# f280015x_pbist_regs register map
Vendor: Texas Instruments
Peripheral module from a debugger description file (folder C2000).
Address unit: 16 bits
Registers are 32-bit, read-write, no defined reset value unless marked. A register's access mark holds for its fields unless they carry their own. Offsets are as the file gives them; lines under a group give offsets from that group; [hi:lo] are bit positions; {n}, {i} and the like mark numbered series; 'fields as' and 'values as' point back to an identical list; <NAME> marks a mode.

## PBIST_REGS — PBIST Registers
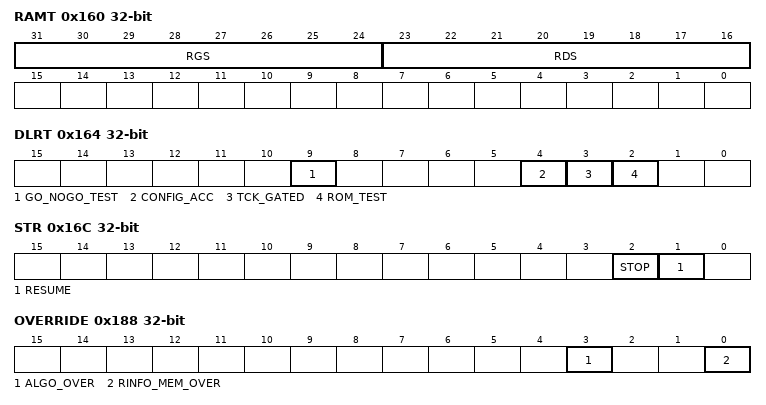
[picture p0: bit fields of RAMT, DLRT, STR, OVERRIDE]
0x160 RAMT — RAM Configuration Register
  [31:24] RGS — RAM Group Select
  [23:16] RDS — Return Data Select
0x164 DLRT — PBIST Data Logger Register
  [9] GO_NOGO_TEST — GO/ NO-GO Testing
  [4] CONFIG_ACC — Config Access
  [3] TCK_GATED
  [2] ROM_TEST — ROM-based testing
0x16C STR — Program Control Register
  [2] STOP — Stops PBIST testing
  [1] RESUME — Resume / Emulation Read
0x180 PACT — PBIST Activate Register
  [0] ENABLE — Enable clocks to PBIST
0x188 OVERRIDE — PBIST Override Register
  [3] ALGO_OVER — ROM Algorithm Override
  [0] RINFO_MEM_OVER — ROM Memory Information Override
0x190 FSRF0 — Fail Status - Port 0
  [31:0] FSRF0 — Fail Status Fail - Port 0
0x194 FSRF1 — Fail Status - Port 1
  [31:0] FSRF1 — Fail Status Fail - Port 1
0x198 FSRC0 — Fail Status Count - Port 0
0x19C FSRC1 — Fail Status Count - Port 1
  [31:0] FSRC0
0x1C4 ALGO — PBIST Algorithm
  [31:0] ALGO — Algo Select Register
0x1C8 RINFOL — RAM Info Mask Register Lower
  [31:0] RINFOL — RINFO Mask Register Lower
0x1CC RINFOU — RAM Info Mask Register Higher
  [31:0] RINFOU — RINFO Mask Register Upper
